# iND83213A register map
Vendor: Indiemicro; Series: Rugby; File version: 1.0
CPU: CM0 r0p1, selectable endian, no MPU, no FPU, 4 interrupt priority bits
Registers are 32-bit, read-write, no defined reset value unless marked. A register's access mark holds for its fields unless they carry their own. Offsets are from the block's base; [hi:lo] are bit positions.

## CRGA — Clock & Reset Generator
Base 0x50000000; register names take the prefix CRGA_
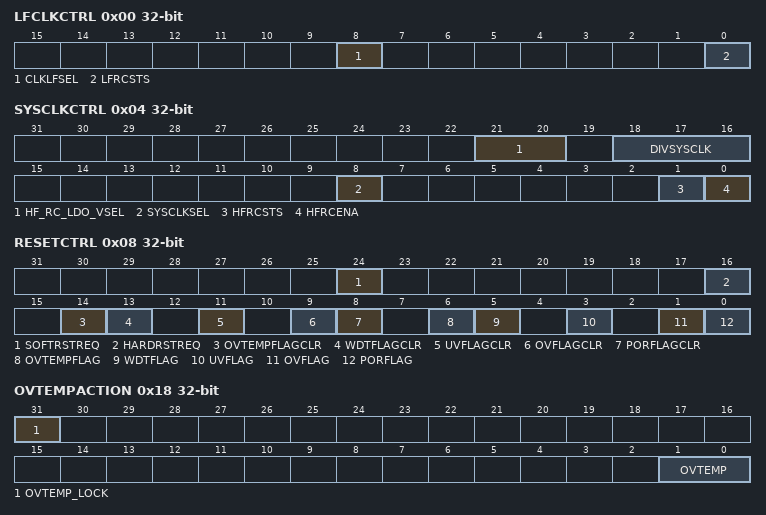
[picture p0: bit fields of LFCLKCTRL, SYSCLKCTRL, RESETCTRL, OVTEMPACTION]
0x00 LFCLKCTRL — Low frequency clock control
  [8] CLKLFSEL — LF Clock Source select. Used to select lf osc mode between, NOTE:The write operation of this field register takes effect by configuring 'SYSCTRLA_SFRS->DEBUG_ACCESS_KEY.DEBUG_ACCESS_KEY = 0x05' 0x0: CLK_LF(LF OSC out) is 256KHz, slow system clock freq is Freq_CLK_LF/2 = 128KHz. 0x1: CLK_LF(LF OSC out) is 256KHz, slow system clock freq is Freq_CLK_LF/16= 16KHz.
  [0] LFRCSTS ro — Slow oscillator status. Will be high when the Low Frequency oscillator is selected
0x04 SYSCLKCTRL — System clock control
  [21:20] HF_RC_LDO_VSEL — 24MHz RC OSC LDO output select. 0x0: 1V45 Selected 0x1: 1V50 Selected 0x2: 1V55 Selected 0x3: 1V65 Selected
  [18:16] DIVSYSCLK — Clock div select. Select the divider ratio on the system clock when using fast oscillator 0x0: No Division. Full Clock speed. 0x1: Div by 2. 0x2: Div by 3. 0x3: Div by 4. 0x4: Div by 5. 0x5: Div by 6. 0x6: Div by 7. 0x7: Div by 8.
  [8] SYSCLKSEL — Clock select. Used to switch between the fast and slow system clocks 0x0: Slow clock 0x1: Fast clock
  [1] HFRCSTS ro — Fast oscillator status. Will be high when High Frequency oscillator is enabled
  [0] HFRCENA — Fast oscillator enable. Setting this bit when the High Frequency oscillator is not running will cause the oscillator to start (the PMU may have already started it). Even though the fast oscillator is running, its output is only used when selected via the clock mux - see CLKSEL. This bit is cleared automatically on entering SLEEP mode
0x08 RESETCTRL — Reset control
  [24] SOFTRSTREQ wo — Soft reset request. Set to trigger a soft reset of chip Autoclear: includes a synchronous reset signal which clears the register on the cycle following write.
  [16] HARDRSTREQ wo — Hard reset request. Set to trigger a hard reset of chip
  [14] OVTEMPFLAGCLR wo — OVTEMP flag clear. Set to clear the OVTEMP flag
  [13] WDTFLAGCLR wo — WDT flag clear. Set to clear the WDT flag
  [11] UVFLAGCLR wo — UV flag clear. Set to clear the UV flag
  [9] OVFLAGCLR wo — OV flag clear. Set to clear the OV flag
  [8] PORFLAGCLR wo — POR flag clear. Set to clear the POR flag
  [6] OVTEMPFLAG ro — Over Temp Violation flag. Set by the hardware when the over temp condition is detected.
  [5] WDTFLAG ro — Watchdog bark flag. Set by the hardware when the watchdog barks.
  [3] UVFLAG ro — Under Voltage Monitor flag. Set by the hardware when the under voltage monitor.
  [1] OVFLAG ro — Over Voltage Monitor flag. Set by the hardware when the over voltage monitor.
  [0] PORFLAG ro — Power on reset flag. Set by the hardware during power-on reset
0x0C MODULERST — Module Reset control
  [7:0] MODULERSTREQ wo — Module Soft reset request. Set to trigger a soft reset of module below. 0x1: ADC Soft reset request 0x2: BUCK Soft reset request 0x4: LINM soft reset request 0x8: LINS soft reset request 0x10: PWM_AUX soft reset request 0x20: PWM soft reset request 0x40: SPI soft reset request 0x80: UART soft reset request Autoclear: includes a synchronous reset signal which clears the register on the cycle following write.
0x10 WDTACTION — Watchdog action
  [0] WDTACTION — Watchdog action. Defines the consequences of watchdog bark being detected by the hardware. 0x0: IRQ generated 0x1: Hard reset generated
0x14 LFCLKKILL — Low frequency clock kill
  [0] KILLLFRC — Kill slow RC oscillator. Setting this bit gates the low frequency RC oscillator input. NOTE:The write operation of this field register takes effect by configuring 'SYSCTRLA_SFRS->DEBUG_ACCESS_KEY.DEBUG_ACCESS_KEY = 0x05'
0x18 OVTEMPACTION
  [31] OVTEMP_LOCK — Set Only bit. Set this bit to lock OVTEMP related bits.
  [1:0] OVTEMP — Over Temperature action. Defines the consequences of over temp condition detected by the hardware. 0x2: No action 0x1: IRQ generated 0x0: Hard reset generated
0x1C OVTEMPCONFIG — OVTEMP configuration
  [5:4] SEL_TSCH — Selecting the temperature sensor channel. Selecting the temperature sensor channel 0x0: channel 1 0x1: channel 2 0x2: channel 3 0x3: channel 4
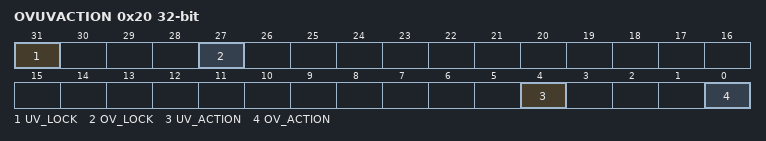
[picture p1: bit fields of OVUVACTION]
0x20 OVUVACTION
  [31] UV_LOCK — Set Only bit. Set this bit to lock UV ACTION related bits.
  [27] OV_LOCK — Set Only bit. Set this bit to lock OV ACTION related bits.
  [4] UV_ACTION — Under Voltage action. Defines the consequences of under voltage condition detected by the hardware. 0x1: No action 0x0: Hard reset generated
  [0] OV_ACTION — Over Voltage action. Defines the consequences of over voltage condition detected by the hardware. 0x1: No action 0x0: Hard reset generated
0x24 MODULEGATEENA — Module Gate control
  [4:0] MODULEGATEENA — Module Gate enable request. Set to enable the clock gate of module below. 0x1: GPIO clock gate Soft enable request 0x2: PWM clock gate Soft enable request 0x4: PWM_AUX clock gate soft enable request 0x8: UART clock gate soft enable request 0x10: SPI clock gate soft enable request
